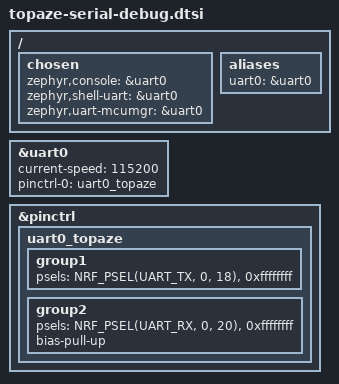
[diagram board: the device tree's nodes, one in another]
/* ============================================================
 * This file is the overlay DTS for topaze that define the UARTS
 *
 * We describe here the peripherals configuration, and so on...
 *
 * l.heywang
 * 01/03/2025
 *
 * ============================================================
 */

// ============================================================
// UARTS and PINCTRL
// ============================================================
// Enable UART drivers with defined settings
&uart0 {
    status = "okay";
    current-speed = <115200>;
    pinctrl-0 = <&uart0_topaze>;
    pinctrl-names = "default";
};

// We're using here default pins for UART0 to use the dk output 
// capabilities, while on the topaze board they're redirected
// to two unused GPIO
&pinctrl {
    uart0_topaze: uart0_topaze {
		group1 {
			psels = <NRF_PSEL(UART_TX, 0, 18)>,
                    <0xffffffff>; // RTS : Value for unused pin.
		};
		group2 {
			psels = <NRF_PSEL(UART_RX, 0, 20)>,
                    <0xffffffff>; // CTS : Value for unused pin.
			bias-pull-up;
		};
	};
};

// Configure the console output as UART0 and 
// set aliases for this module
/ {
    chosen {
        zephyr,console = &uart0;
        zephyr,shell-uart = &uart0;
		zephyr,uart-mcumgr = &uart0;
    };

    aliases {
        uart0 = &uart0;
    };
};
